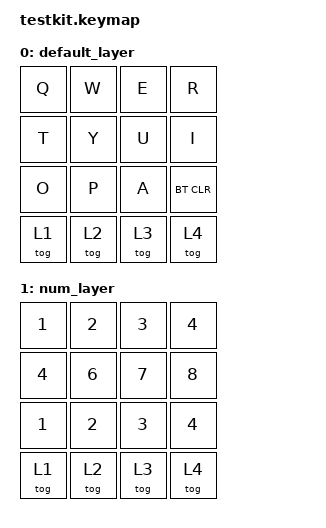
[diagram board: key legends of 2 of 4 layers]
#include <behaviors.dtsi>
#include <dt-bindings/zmk/keys.h>
#include <dt-bindings/zmk/bt.h>

/ {
    keymap {
        compatible = "zmk,keymap";

        default_layer {

            bindings = <
    &kp Q &kp W &kp E &kp R
    &kp T &kp Y &kp U &kp I
    &kp O &kp P &kp A &bt BT_CLR
    &tog 1 &tog 2 &tog 3 &tog 4
            >;

        };

        num_layer {
            bindings = <
    &kp N1 &kp N2 &kp N3 &kp N4
    &kp N4 &kp N6 &kp N7 &kp N8
    &kp N1 &kp N2 &kp N3 &kp N4
    &tog 1 &tog 2 &tog 3 &tog 4
            >;
        };

        lower_layer {
            bindings = <
    &bt BT_CLR &none        &reset       &bootloader
    &trans     &bt BT_SEL 3 &bt BT_SEL 4 &none
    &none      &bt BT_SEL 0 &bt BT_SEL 1 &bt BT_SEL 2
            >;
        };

        raise_layer {
            bindings = <
    &kp 0x68 &kp 0x69 &kp 0x6A &kp 0x6B
    &kp 0x6C &kp 0x6D &kp 0x6E &kp 0x6F
    &trans   &kp 0x70 &kp 0x71 &kp 0x72
            >;
        };
    };
};
